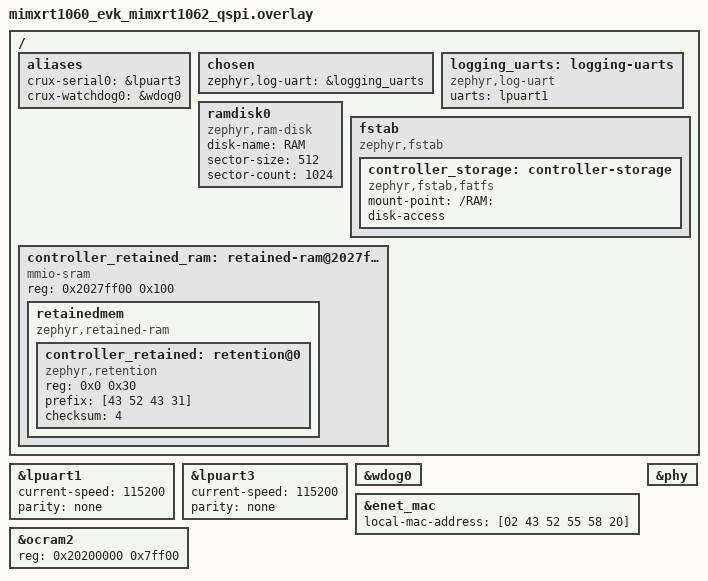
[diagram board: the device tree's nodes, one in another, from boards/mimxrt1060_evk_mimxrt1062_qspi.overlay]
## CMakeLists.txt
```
# SPDX-License-Identifier: Apache-2.0

# The product's application. The controller framework is a Zephyr module of the product's west
# workspace, found by west: this file names no path, source or include directory of the framework.
# The application links the interface target of the framework and calls its image function, which
# adds the route table and the page of web management. Board values live in boards/, not here.

cmake_minimum_required(VERSION 3.20.0)
find_package(Zephyr REQUIRED HINTS $ENV{ZEPHYR_BASE})
project(product LANGUAGES C)

target_sources(app PRIVATE src/main.c)
target_compile_options(app PRIVATE -Wall -Wextra -Werror)
target_link_libraries(app PRIVATE controller::framework crux::logging)
controller_framework_image()
```

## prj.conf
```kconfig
# The product's configuration on every board: the controller framework with health supervision, web
# management on Crux's Mbed TLS profile, the serial command line and time synchronisation. The
# board files in boards/ hold every value that depends on the board.
#
# This is a development configuration: with boards/native_sim_native_64.conf it runs on native_sim with the
# simulator's test entropy and without a watchdog. README.md, "Make a product build", lists what a
# product build changes. Every size, priority and timeout is a starting value that was not measured.
CONFIG_CRUX_CONTROLLER_FRAMEWORK=y
CONFIG_STD_C17=y
# west spdx needs this.
CONFIG_BUILD_OUTPUT_META=y

# Health supervision: the task watchdog without a hardware fallback, and Crux Reboot, whose worker
# the framework replaces with its own reboot thread. The main thread runs the start function in the
# startup band (8), below the supervisor (7).
CONFIG_TASK_WDT=y
CONFIG_TASK_WDT_HW_FALLBACK=n
CONFIG_CRUX_REBOOT=y
CONFIG_MAIN_THREAD_PRIORITY=8

# Crux Logging on the UART of the devicetree's zephyr,log-uart (the board files choose it).
CONFIG_CRUX_TIME=y
CONFIG_CRUX_LOGGING=y
CONFIG_SERIAL=y
CONFIG_UART_INTERRUPT_DRIVEN=y
CONFIG_UART_USE_RUNTIME_CONFIGURE=y
CONFIG_LOG=y
CONFIG_LOG_MODE_DEFERRED=y
CONFIG_LOG_MODE_OVERFLOW=n
CONFIG_LOG_BLOCK_IN_THREAD=n
CONFIG_LOG_PROCESS_THREAD=y
CONFIG_LOG_PROCESS_THREAD_STACK_SIZE=2048
CONFIG_LOG_PROCESS_THREAD_CUSTOM_PRIORITY=y
CONFIG_LOG_PROCESS_THREAD_PRIORITY=14
CONFIG_LOG_MAX_LEVEL=4
CONFIG_LOG_DEFAULT_LEVEL=0
CONFIG_LOG_RUNTIME_FILTERING=n
CONFIG_LOG_BACKEND_UART=y
CONFIG_LOG_BACKEND_UART_ASYNC=n
CONFIG_LOG_BACKEND_SHOW_LEVEL=y
CONFIG_LOG_BACKEND_CRLF_NONE=n
CONFIG_UART_CONSOLE=y
CONFIG_LOG_PRINTK=y
CONFIG_STDOUT_CONSOLE=n
CONFIG_CONSOLE_HANDLER=n
CONFIG_CONSOLE_SUBSYS=n
CONFIG_EARLY_CONSOLE=n
CONFIG_SHELL=n
CONFIG_BOOT_BANNER=n

# Time synchronisation through the Zephyr SNTP library; the board files name the server.
CONFIG_SNTP=y

# The serial command line: the Crux console with its first-account setup on the UART of the alias
# crux-serial0, in the device management band.
CONFIG_CRUX_SERIAL=y
CONFIG_CRUX_CLI=y
CONFIG_CRUX_CLI_CONSOLE=y
CONFIG_CRUX_CLI_CONSOLE_PRIORITY=11

# Web management on Crux's Mbed TLS profile.
CONFIG_MBEDTLS=y
CONFIG_MBEDTLS_PSA_CRYPTO_C=y
CONFIG_PSA_CRYPTO_PROVIDER_MBEDTLS=y
CONFIG_MBEDTLS_ENABLE_HEAP=y
CONFIG_MBEDTLS_HEAP_SIZE=120000
CONFIG_MBEDTLS_SSL_IN_CONTENT_LEN=16384
CONFIG_MBEDTLS_SSL_OUT_CONTENT_LEN=16384
CONFIG_MBEDTLS_SSL_PROTO_TLS1_2=y
CONFIG_MBEDTLS_SSL_PROTO_TLS1_3=y
CONFIG_MBEDTLS_SSL_TLS1_3_KEY_EXCHANGE_MODE_EPHEMERAL_ENABLED=y
CONFIG_MBEDTLS_KEY_EXCHANGE_ECDHE_ECDSA_ENABLED=y
CONFIG_MBEDTLS_CIPHERSUITE_TLS_ECDHE_ECDSA_WITH_AES_128_GCM_SHA256=y
CONFIG_MBEDTLS_CIPHERSUITE_TLS1_3_AES_128_GCM_SHA256=y
CONFIG_PSA_WANT_ALG_SHA_256=y
CONFIG_PSA_WANT_ECC_SECP_R1_256=y
CONFIG_PSA_WANT_ALG_ECDSA=y
CONFIG_PSA_WANT_ALG_ECDH=y
CONFIG_PSA_WANT_ALG_GCM=y
CONFIG_PSA_WANT_KEY_TYPE_AES=y
CONFIG_PSA_WANT_ALG_HMAC=y
CONFIG_PSA_WANT_KEY_TYPE_HMAC=y
CONFIG_PSA_WANT_ALG_HKDF=y
CONFIG_PSA_WANT_ALG_PBKDF2_HMAC=y
CONFIG_PSA_WANT_ALG_TLS12_PRF=y
CONFIG_PSA_WANT_KEY_TYPE_ECC_PUBLIC_KEY=y
CONFIG_PSA_WANT_KEY_TYPE_ECC_KEY_PAIR_IMPORT=y
CONFIG_PSA_WANT_KEY_TYPE_ECC_KEY_PAIR_EXPORT=y
CONFIG_PSA_WANT_KEY_TYPE_ECC_KEY_PAIR_GENERATE=y
CONFIG_PSA_WANT_KEY_TYPE_ECC_KEY_PAIR_DERIVE=y
CONFIG_MBEDTLS_PK_WRITE_C=y
CONFIG_CRUX_PSA_THREADING=y

# The Crux services of device management.
CONFIG_CRUX_ACCESS=y
CONFIG_CRUX_CONFIG_SERVICE=y
CONFIG_CRUX_MGMT_STATUS=y
CONFIG_CRUX_TLS_CERTIFICATE=y
CONFIG_CRUX_WEB=y
CONFIG_CRUX_WEB_SESSION=y
CONFIG_CRUX_WEB_MANAGEMENT=y
CONFIG_CRUX_SYSTEM=y
CONFIG_CRUX_NETIF=y
CONFIG_WATCHDOG=y
CONFIG_HWINFO=y
CONFIG_REBOOT=y
CONFIG_CRUX_WEB_PORT=443
CONFIG_CRUX_WEB_BACKLOG=4
CONFIG_HTTP_SERVER_MAX_CLIENTS=3
CONFIG_HTTP_SERVER_STACK_SIZE=16384
CONFIG_CRUX_WEB_SESSION_WORKER_PRIORITY=11
CONFIG_CRUX_WEB_MANAGEMENT_WORKER_PRIORITY=11
CONFIG_CRUX_SECURITY_EVENT_DRAIN_PRIORITY=11
# The entropy source comes from the board files.
CONFIG_ENTROPY_GENERATOR=y

# Crux File on a FAT volume of the devicetree's fstab entry controller_storage, which the framework
# mounts and formats when it is blank. The board files choose the disk and the provider.
CONFIG_FILE_SYSTEM=y
CONFIG_FILE_SYSTEM_MKFS=y
CONFIG_FAT_FILESYSTEM_ELM=y
CONFIG_FS_FATFS_LFN=y
CONFIG_FS_FATFS_LFN_MODE_STACK=y
CONFIG_FS_FATFS_MAX_LFN=127
CONFIG_FS_FATFS_MOUNT_MKFS=n
CONFIG_FS_FATFS_REENTRANT=y
CONFIG_FS_FATFS_NUM_FILES=6
CONFIG_DISK_DRIVERS=y
CONFIG_DISK_DRIVER_RAM=y

# The network with TCP and Zephyr's TLS socket layer; the board files give the interface.
CONFIG_NETWORKING=y
CONFIG_NET_IPV4=y
CONFIG_NET_IPV6=n
CONFIG_NET_TCP=y
CONFIG_NET_UDP=y
CONFIG_NET_SOCKETS=y
CONFIG_NET_SOCKETS_SOCKOPT_TLS=y
CONFIG_TLS_CREDENTIALS=y
CONFIG_TLS_MAX_CREDENTIALS_NUMBER=4
CONFIG_NET_SOCKETS_TLS_MAX_CONTEXTS=6
CONFIG_ZVFS_OPEN_MAX=48
CONFIG_ZVFS_POLL_MAX=24
CONFIG_ZVFS_EVENTFD=y
CONFIG_NET_MAX_CONTEXTS=32
CONFIG_NET_MAX_CONN=32

# Threads and stacks, for the status service and for debugging.
CONFIG_HEAP_MEM_POOL_SIZE=32768
CONFIG_INIT_STACKS=y
CONFIG_THREAD_STACK_INFO=y
CONFIG_THREAD_NAME=y
CONFIG_THREAD_MONITOR=y
```

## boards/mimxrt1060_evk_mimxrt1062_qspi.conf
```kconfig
# The product on the reference board, the RT1060-EVKB (board target mimxrt1060_evk@B/mimxrt1062/qspi).
# Zephyr merges this file with prj.conf for that target. The values are those of the framework's
# base image on this board (app/conf/base.conf of crux-controller at the commit that the copy was
# made from); none was measured for a product.
#
# - Health supervision arms the Crux System watchdog and keeps the boot counter and the last-fault
#   record in the retained region of the overlay, without mutexes, because the fatal error handler
#   writes it.
# - Stack hardening of a product build (requirement SEC6): compiler stack canaries and the MPU stack
#   guard of the Cortex-M7.
# - The network is the board's Ethernet port with a static address, configured before main(). The
#   framework's SNTP server is its default, 192.168.77.1.
# - Crux File is a FAT volume on a RAM disk in the SDRAM, so nothing persists across a reset. The
#   entropy is the i.MX RT random source (TRNG), which the framework requires on a board.
CONFIG_RETAINED_MEM=y
CONFIG_RETAINED_MEM_MUTEX_FORCE_DISABLE=y
CONFIG_RETENTION=y
CONFIG_RETENTION_MUTEX_FORCE_DISABLE=y
CONFIG_STACK_CANARIES=y
CONFIG_HW_STACK_PROTECTION=y
CONFIG_MAIN_STACK_SIZE=16384
CONFIG_LOG_BUFFER_SIZE=4096

CONFIG_CRUX_SOCKETS=y
CONFIG_GPIO=y
CONFIG_NET_DHCPV4=n
CONFIG_NET_CONFIG_SETTINGS=y
CONFIG_NET_CONFIG_AUTO_INIT=y
CONFIG_NET_CONFIG_NEED_IPV4=y
CONFIG_NET_CONFIG_MY_IPV4_ADDR="192.168.77.2"
CONFIG_NET_CONFIG_MY_IPV4_NETMASK="255.255.255.0"
CONFIG_NET_CONFIG_MY_IPV4_GW=""
CONFIG_POSIX_SYSTEM_INTERFACES=y
CONFIG_POSIX_NETWORKING=y
CONFIG_POSIX_DEVICE_IO=y
CONFIG_POSIX_FD_MGMT=y
CONFIG_POSIX_TIMERS=y
CONFIG_POSIX_MONOTONIC_CLOCK=y
CONFIG_PHY_MONITOR_PERIOD=500
CONFIG_CRUX_WEB_BIND_ADDRESS="192.168.77.2"
CONFIG_NET_TCP_ISN_RFC6528=y
CONFIG_NET_BUF_DATA_SIZE=128
CONFIG_NET_TCP_MAX_RECV_WINDOW_SIZE=5840
CONFIG_NET_TCP_MAX_SEND_WINDOW_SIZE=5840
CONFIG_NET_BUF_RX_COUNT=1024
CONFIG_NET_BUF_TX_COUNT=768
CONFIG_NET_PKT_RX_COUNT=192
CONFIG_NET_PKT_TX_COUNT=32
CONFIG_ETH_NXP_ENET_RX_BUFFERS=6

CONFIG_DISK_DRIVER_SDMMC=n
CONFIG_IMX_USDHC=n
CONFIG_CRUX_FILE_FATFS_RT1060_RAM_DISK=y
```

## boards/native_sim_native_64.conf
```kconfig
# The product on native_sim, for development and CI only. Zephyr merges this file with prj.conf for
# every native_sim target (native_sim and native_sim/native/64).
#
# - The entropy is the simulator's test source, so a key made here protects nothing; the framework
#   refuses a test source on any other board.
# - native_sim has no watchdog behind the alias crux-watchdog0, so the watchdog is not armed. The
#   start without a watchdog of decision D14 lets this build start the application; a product build
#   never sets it.
# - The network is Zephyr's loopback interface, with no host network: web management listens on
#   127.0.0.1 inside the process, and no SNTP server answers there.
# - Crux File uses the simulator's provider on a RAM disk, so nothing persists.
# - Crux Logging writes to the first PTY UART, which is the program's standard output.
CONFIG_CRUX_CONTROLLER_START_WITHOUT_WATCHDOG=y
CONFIG_CRUX_CONTROLLER_TIME_SERVER="127.0.0.1"
CONFIG_CRUX_WEB_BIND_ADDRESS="127.0.0.1"
CONFIG_CRUX_FILE_FATFS_SIMULATOR=y
# The web adapter refuses the external libc of native_sim.
CONFIG_PICOLIBC=y
CONFIG_MAIN_STACK_SIZE=32768
CONFIG_LOG_BUFFER_SIZE=8192
CONFIG_LOG_BACKEND_NATIVE_POSIX=n
CONFIG_UART_NATIVE_PTY_0_ON_STDINOUT=y

# Crux Serial accepts only an emulated UART on native_sim, so the console owns one (the overlay).
CONFIG_EMUL=y
CONFIG_UART_EMUL=y

CONFIG_NET_DRIVERS=y
CONFIG_NET_LOOPBACK=y
CONFIG_NET_PKT_RX_COUNT=64
CONFIG_NET_PKT_TX_COUNT=64
CONFIG_NET_BUF_RX_COUNT=256
CONFIG_NET_BUF_TX_COUNT=256
```

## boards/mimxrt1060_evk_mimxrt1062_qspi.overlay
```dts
/* SPDX-License-Identifier: Apache-2.0 */
/* The devicetree of the product on the reference board, the RT1060-EVKB. The nodes are those of the
 * framework's base image on this board (the overlays of app/boards of crux-controller at the commit
 * that the copy was made from). The wiring of LPUART3 to a terminal and the retained region's
 * behaviour across resets have not been checked on a board. */

/* Crux Logging writes to LPUART1; the Crux serial console owns LPUART3 through the alias
 * crux-serial0. The two never share a UART. */
/ {
    aliases {
        crux-serial0 = &lpuart3;
        crux-watchdog0 = &wdog0;
        /delete-property/ led0;
    };

    chosen {
        zephyr,log-uart = &logging_uarts;
    };

    logging_uarts: logging-uarts {
        compatible = "zephyr,log-uart";
        uarts = <&lpuart1>;
    };
};

&lpuart1 {
    status = "okay";
    current-speed = <115200>;
    parity = "none";
};

&lpuart3 {
    status = "okay";
    current-speed = <115200>;
    parity = "none";
};

/* Crux System owns WDOG1 through the alias crux-watchdog0; the framework arms it. */
&wdog0 {
    status = "okay";
};

/* The Ethernet composition of this board, with a locally administered MAC address. Replace the
 * address with the product's own. GPIO1.9 belongs to the PHY reset, and the PHY uses the native
 * 500 ms monitor. */
/delete-node/ &green_led;

&enet_mac {
    /delete-property/ zephyr,random-mac-address;
    local-mac-address = [02 43 52 55 58 20];
};

&phy {
    /delete-property/ int-gpios;
};

/* The store: a FAT volume on a RAM disk of 524,288 bytes in the SDRAM, through the fstab entry
 * controller_storage, which the framework mounts and formats at every start. */
/ {
    ramdisk0 {
        compatible = "zephyr,ram-disk";
        disk-name = "RAM";
        sector-size = <512>;
        sector-count = <1024>;
    };

    fstab {
        compatible = "zephyr,fstab";
        controller_storage: controller-storage {
            compatible = "zephyr,fstab,fatfs";
            mount-point = "/RAM:";
            disk-access;
        };
    };
};

/* The retained region of health supervision: the boot counter, the operator reset marker and the
 * last-fault record, as a Zephyr retention area of 48 bytes with a prefix and a CRC-32, over a
 * retained RAM area at the end of OCRAM2. OCRAM2 shrinks by the 256 bytes of the area, so that the
 * link never places anything there. */
&ocram2 {
    reg = <0x20200000 0x7ff00>;
};

/ {
    controller_retained_ram: retained-ram@2027ff00 {
        compatible = "mmio-sram";
        reg = <0x2027ff00 0x100>;
        status = "okay";

        retainedmem {
            compatible = "zephyr,retained-ram";
            status = "okay";
            #address-cells = <1>;
            #size-cells = <1>;

            controller_retained: retention@0 {
                compatible = "zephyr,retention";
                status = "okay";
                reg = <0x0 0x30>;
                prefix = [43 52 43 31];
                checksum = <4>;
            };
        };
    };
};
```

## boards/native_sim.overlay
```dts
/* SPDX-License-Identifier: Apache-2.0 */
/* The devicetree of the product on native_sim, for development and CI only.
 *
 * - Crux Logging writes to uart0, which boards/native_sim.conf connects to standard output.
 * - The Crux serial console owns an emulated UART through the alias crux-serial0, because Crux
 *   Serial accepts only an emulated UART on native_sim. Nothing is attached to it.
 * - The store is a RAM disk with the fstab entry controller_storage, which the framework mounts and
 *   formats at every start. */
&uart0 {
    current-speed = <115200>;
};

/ {
    aliases {
        crux-serial0 = &console_emul;
    };

    chosen {
        zephyr,log-uart = &logging_uarts;
    };

    logging_uarts: logging-uarts {
        compatible = "zephyr,log-uart";
        uarts = <&uart0>;
    };

    console_emul: console-emul {
        compatible = "zephyr,uart-emul";
        current-speed = <115200>;
        rx-fifo-size = <1024>;
        tx-fifo-size = <1024>;
        status = "okay";
    };

    ramdisk0 {
        compatible = "zephyr,ram-disk";
        disk-name = "RAM";
        sector-size = <512>;
        sector-count = <1024>;
    };

    fstab {
        compatible = "zephyr,fstab";
        controller_storage: controller-storage {
            compatible = "zephyr,fstab,fatfs";
            mount-point = "/RAM:";
            disk-access;
        };
    };
};
```

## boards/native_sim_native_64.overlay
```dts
/* SPDX-License-Identifier: Apache-2.0 */
/* The devicetree of the product on native_sim, for development and CI only.
 *
 * - Crux Logging writes to uart0, which boards/native_sim_native_64.conf connects to standard output.
 * - The Crux serial console owns an emulated UART through the alias crux-serial0, because Crux
 *   Serial accepts only an emulated UART on native_sim. Nothing is attached to it.
 * - The store is a RAM disk with the fstab entry controller_storage, which the framework mounts and
 *   formats at every start. */
&uart0 {
    current-speed = <115200>;
};

/ {
    aliases {
        crux-serial0 = &console_emul;
    };

    chosen {
        zephyr,log-uart = &logging_uarts;
    };

    logging_uarts: logging-uarts {
        compatible = "zephyr,log-uart";
        uarts = <&uart0>;
    };

    console_emul: console-emul {
        compatible = "zephyr,uart-emul";
        current-speed = <115200>;
        rx-fifo-size = <1024>;
        tx-fifo-size = <1024>;
        status = "okay";
    };

    ramdisk0 {
        compatible = "zephyr,ram-disk";
        disk-name = "RAM";
        sector-size = <512>;
        sector-count = <1024>;
    };

    fstab {
        compatible = "zephyr,fstab";
        controller_storage: controller-storage {
            compatible = "zephyr,fstab,fatfs";
            mount-point = "/RAM:";
            disk-access;
        };
    };
};
```

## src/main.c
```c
/* SPDX-License-Identifier: Apache-2.0 */

/*
 * The product's main(): it passes the product's descriptor to the start function of the controller
 * framework, which starts the framework services and then calls the entries below on its
 * application thread (<controller/framework.h> states the rules of each entry).
 *
 * The entries do nothing yet except log. Replace each body with the product's own work:
 *   init        register the watchdog channels, status items and parameter tables that the product
 *               needs (controller_app_channel_register() and <controller/framework_management.h>);
 *               nothing is registered later;
 *   start       create the product's threads with Zephyr, each feeding its own channel;
 *   stop        end every thread that start created, then return;
 *   safe_state  put the outputs into the product's safe state; it never blocks, takes no lock,
 *               allocates nothing and logs nothing.
 */

#include <stddef.h>

#include <controller/framework.h>
#include <crux/logging.h>

/* The log tag of the product's records (letters, digits, '_', '.', '-'). */
#define PRODUCT_LOG_TAG "product"

static void product_log(const char *text)
{
    (void)crux_log_write(CRUX_LOG_INFO, PRODUCT_LOG_TAG, text);
}

static int product_init(controller_app_context_t *context)
{
    (void)context;
    product_log("init");
    return 0;
}

static int product_start(controller_app_context_t *context)
{
    (void)context;
    product_log("start");
    return 0;
}

static int product_stop(controller_app_context_t *context, controller_app_stop_reason_t reason)
{
    (void)context;
    (void)reason;
    product_log("stop");
    return 0;
}

static void product_safe_state(controller_app_context_t *context)
{
    (void)context;
}

/* The descriptor stays valid for the program's life. */
static const controller_app_t product_app = {
    .init = product_init,
    .start = product_start,
    .stop = product_stop,
    .safe_state = product_safe_state,
    .user_data = NULL,
};

int main(void)
{
    return controller_framework_start(&product_app) == CONTROLLER_FRAMEWORK_OK ? 0 : -1;
}
```
